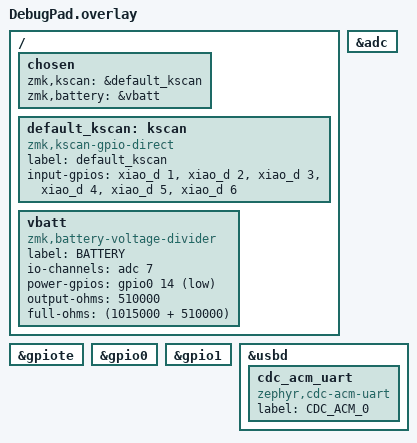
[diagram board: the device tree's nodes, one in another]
#include <nordic/nrf52840_qiaa.dtsi>

/ {
  chosen {
    zmk,kscan = &default_kscan;
    zmk,battery = &vbatt;
  };

  default_kscan: kscan {
    compatible = "zmk,kscan-gpio-direct";
    label = "default_kscan";

    input-gpios =
        <&xiao_d 1 (GPIO_ACTIVE_HIGH | GPIO_PULL_DOWN)>,
        <&xiao_d 2 (GPIO_ACTIVE_HIGH | GPIO_PULL_DOWN)>,
        <&xiao_d 3 (GPIO_ACTIVE_HIGH | GPIO_PULL_DOWN)>,
        <&xiao_d 4 (GPIO_ACTIVE_HIGH | GPIO_PULL_DOWN)>,
        <&xiao_d 5 (GPIO_ACTIVE_HIGH | GPIO_PULL_DOWN)>,
        <&xiao_d 6 (GPIO_ACTIVE_HIGH | GPIO_PULL_DOWN)>;
  };

  vbatt: vbatt {
		compatible = "zmk,battery-voltage-divider";
		label = "BATTERY";
		io-channels = <&adc 7>;
		power-gpios = <&gpio0 14 (GPIO_OPEN_DRAIN | GPIO_ACTIVE_LOW)>;
		output-ohms = <510000>;
		full-ohms = <(1015000 + 510000)>;
	};
};

&adc {
	status = "okay";
};

&gpiote {
	status = "okay";
};

&gpio0 {
	status = "okay";
};

&gpio1 {
	status = "okay";
};

&usbd {
  status = "okay";

	cdc_acm_uart: cdc_acm_uart {
		compatible = "zephyr,cdc-acm-uart";
		label = "CDC_ACM_0";
	};
};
